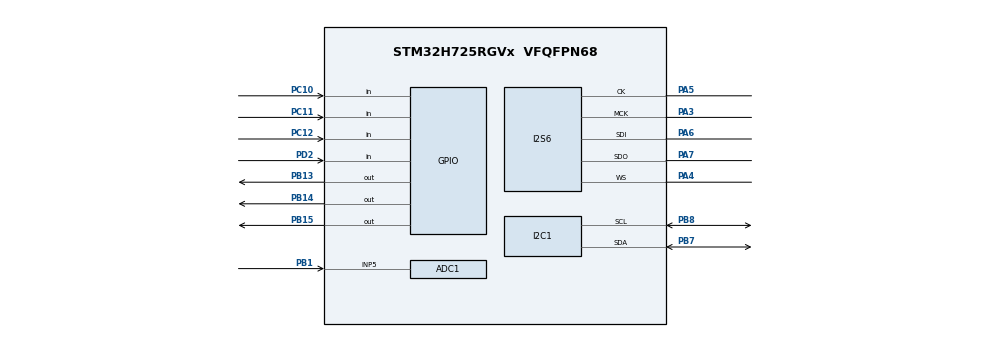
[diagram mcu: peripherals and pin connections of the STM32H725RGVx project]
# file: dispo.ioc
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ADC1.Channel-0\#ChannelRegularConversion=ADC_CHANNEL_5
ADC1.ContinuousConvMode=DISABLE
ADC1.EOCSelection=ADC_EOC_SINGLE_CONV
ADC1.NbrOfConversionFlag=1
ADC1.OffsetNumber-0\#ChannelRegularConversion=ADC_OFFSET_NONE
ADC1.OffsetSignedSaturation-0\#ChannelRegularConversion=DISABLE
ADC1.Overrun=ADC_OVR_DATA_PRESERVED
ADC1.Rank-0\#ChannelRegularConversion=1
ADC1.SamplingTime-0\#ChannelRegularConversion=ADC_SAMPLETIME_1CYCLE_5
ADC1.master=1
Bdma.Request0=SPI6_RX
Bdma.Request1=SPI6_TX
Bdma.RequestsNb=2
Bdma.SPI6_RX.0.Direction=DMA_PERIPH_TO_MEMORY
Bdma.SPI6_RX.0.EventEnable=DISABLE
Bdma.SPI6_RX.0.Instance=BDMA_Channel0
Bdma.SPI6_RX.0.MemDataAlignment=DMA_MDATAALIGN_HALFWORD
Bdma.SPI6_RX.0.MemInc=DMA_MINC_ENABLE
Bdma.SPI6_RX.0.Mode=DMA_CIRCULAR
Bdma.SPI6_RX.0.PeriphDataAlignment=DMA_PDATAALIGN_HALFWORD
Bdma.SPI6_RX.0.PeriphInc=DMA_PINC_DISABLE
Bdma.SPI6_RX.0.Polarity=HAL_DMAMUX_REQ_GEN_RISING
Bdma.SPI6_RX.0.Priority=DMA_PRIORITY_HIGH
Bdma.SPI6_RX.0.RequestNumber=1
Bdma.SPI6_RX.0.SignalID=NONE
Bdma.SPI6_RX.0.SyncEnable=DISABLE
Bdma.SPI6_RX.0.SyncPolarity=HAL_DMAMUX_SYNC_NO_EVENT
Bdma.SPI6_RX.0.SyncRequestNumber=1
Bdma.SPI6_RX.0.SyncSignalID=NONE
Bdma.SPI6_TX.1.Direction=DMA_MEMORY_TO_PERIPH
Bdma.SPI6_TX.1.EventEnable=DISABLE
Bdma.SPI6_TX.1.Instance=BDMA_Channel1
Bdma.SPI6_TX.1.MemDataAlignment=DMA_MDATAALIGN_HALFWORD
Bdma.SPI6_TX.1.MemInc=DMA_MINC_ENABLE
Bdma.SPI6_TX.1.Mode=DMA_CIRCULAR
Bdma.SPI6_TX.1.PeriphDataAlignment=DMA_PDATAALIGN_HALFWORD
Bdma.SPI6_TX.1.PeriphInc=DMA_PINC_DISABLE
Bdma.SPI6_TX.1.Polarity=HAL_DMAMUX_REQ_GEN_RISING
Bdma.SPI6_TX.1.Priority=DMA_PRIORITY_HIGH
Bdma.SPI6_TX.1.RequestNumber=1
Bdma.SPI6_TX.1.SignalID=NONE
Bdma.SPI6_TX.1.SyncEnable=DISABLE
Bdma.SPI6_TX.1.SyncPolarity=HAL_DMAMUX_SYNC_NO_EVENT
Bdma.SPI6_TX.1.SyncRequestNumber=1
Bdma.SPI6_TX.1.SyncSignalID=NONE
FREERTOS.Tasks01=defaultTask,24,128,StartDefaultTask,Default,NULL,Dynamic,NULL,NULL
FREERTOS.configUSE_NEWLIB_REENTRANT=1
I2C1.Timing=0x10C0ECFF
I2S6.AudioFreq=I2S_AUDIOFREQ_48K
I2S6.ErrorAudioFreq=-2.34 %
I2S6.Instance=SPI$Index
I2S6.RealAudioFreq=46.875 KHz
Mcu.Family=STM32H7
Mcu.Name=STM32H725RGVx
Mcu.Package=VFQFPN68
NVIC.BDMA_Channel0_IRQn=true\:5\:0\:false\:false\:true\:true\:false\:true\:true
NVIC.BDMA_Channel1_IRQn=true\:5\:0\:false\:false\:true\:true\:false\:true\:true
NVIC.PriorityGroup=NVIC_PRIORITYGROUP_4
NVIC.TIM1_UP_IRQn=true\:15\:0\:false\:false\:true\:false\:false\:true\:true
NVIC.TimeBase=TIM1_UP_IRQn
NVIC.TimeBaseIP=TIM1
PA13(JTMS/SWDIO).Mode=Trace_Asynchronous_SW
PA13(JTMS/SWDIO).Signal=DEBUG_JTMS-SWDIO
PA14(JTCK/SWCLK).Mode=Trace_Asynchronous_SW
PA14(JTCK/SWCLK).Signal=DEBUG_JTCK-SWCLK
PA3.Mode=Master_Clock_Activated
PA3.Signal=I2S6_MCK
PA4.Mode=Full_Duplex_Master
PA4.Signal=I2S6_WS
PA5.Mode=Full_Duplex_Master
PA5.Signal=I2S6_CK
PA6.Mode=Full_Duplex_Master
PA6.Signal=I2S6_SDI
PA7.Mode=Full_Duplex_Master
PA7.Signal=I2S6_SDO
PB1.Signal=ADCx_INP5
PB13.Signal=GPIO_Output
PB14.Signal=GPIO_Output
PB15.Signal=GPIO_Output
PB3(JTDO/TRACESWO).Mode=Trace_Asynchronous_SW
PB3(JTDO/TRACESWO).Signal=DEBUG_JTDO-SWO
PB7.Mode=I2C
PB7.Signal=I2C1_SDA
PB8.Mode=I2C
PB8.Signal=I2C1_SCL
PC10.Signal=GPIO_Input
PC11.Signal=GPIO_Input
PC12.Signal=GPIO_Input
PD2.Signal=GPIO_Input
PH0-OSC_IN.Mode=HSE-External-Oscillator
PH0-OSC_IN.Signal=RCC_OSC_IN
PH1-OSC_OUT.Mode=HSE-External-Oscillator
PH1-OSC_OUT.Signal=RCC_OSC_OUT
ProjectManager.HeapSize=0x200
ProjectManager.StackSize=0x400
ProjectManager.TargetToolchain=CMake
RCC.ADCCLockSelection=RCC_ADCCLKSOURCE_PLL3
RCC.ADCFreq_Value=2000000
RCC.APB1Freq_Value=100000000
RCC.APB2Freq_Value=100000000
RCC.APB3Freq_Value=100000000
RCC.APB4Freq_Value=100000000
RCC.CKPERSourceSelection=RCC_CLKPSOURCE_HSE
RCC.CortexFreq_Value=400000000
RCC.D1PPRE=RCC_APB3_DIV2
RCC.D2PPRE1=RCC_APB1_DIV2
RCC.D2PPRE2=RCC_APB2_DIV2
RCC.D3PPRE=RCC_APB4_DIV2
RCC.DIVM1=16
RCC.DIVM2=8
RCC.DIVN1=200
RCC.DIVN2=96
RCC.DIVN3=150
RCC.DIVP1=1
RCC.DIVP2=4
RCC.DIVQ2=4
RCC.DIVR3=75
RCC.HCLKFreq_Value=200000000
RCC.HPRE=RCC_HCLK_DIV2
RCC.HSE_VALUE=32000000
RCC.PLL2FRACN=0
RCC.PLL2_VCI_Range=RCC_PLL2VCIRANGE_3
RCC.PLL3FRACN=0
RCC.PLLFRACN=0
RCC.PLLSourceVirtual=RCC_PLLSOURCE_HSE
RCC.SPI6CLockSelection=RCC_SPI6CLKSOURCE_PLL2
RCC.SYSCLKFreq_VALUE=400000000
RCC.SYSCLKSource=RCC_SYSCLKSOURCE_PLLCLK
RCC.USBCLockSelection=RCC_USBCLKSOURCE_PLL3
RCC.USBFreq_Value=75000000
SH.ADCx_INP5.0=ADC1_INP5,IN5-Single-Ended
VP_FREERTOS_VS_CMSIS_V2.Mode=CMSIS_V2
VP_SYS_VS_tim1.Mode=TIM1
board=custom

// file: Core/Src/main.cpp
/* USER CODE BEGIN Header */
/**
  ******************************************************************************
  * @file           : main.c
  * @brief          : Main program body
  ******************************************************************************
  * @attention
  *
  * Copyright (c) 2026 STMicroelectronics.
  * All rights reserved.
  *
  * This software is licensed under terms that can be found in the LICENSE file
  * in the root directory of this software component.
  * If no LICENSE file comes with this software, it is provided AS-IS.
  *
  ******************************************************************************
  */
/* USER CODE END Header */
#include "main.h"
#include "FreeRTOS.h"
#include "cmsis_os2.h"
#include "adc.h"
#include "bdma.h"
#include "i2c.h"
#include "i2s.h"
#include "gpio.h"

/* USER CODE BEGIN Includes */
#include "audio_proc.hpp"
/* USER CODE END Includes */

void SystemClock_Config(void);
extern void MX_FREERTOS_Init(void);

int main(void)
{

  /* MCU Configuration--------------------------------------------------------*/

  /* Reset of all peripherals, Initializes the Flash interface and the Systick. */
  HAL_Init();

  /* Configure the system clock */
  SystemClock_Config();

  /* Initialize all configured peripherals */
  MX_GPIO_Init();
  MX_BDMA_Init();
  MX_I2C1_Init();
  MX_ADC1_Init();
  MX_I2S6_Init();

  /* Init scheduler */
  osKernelInitialize();  /* Call init function for freertos objects (in cmsis_os2.c) */
  MX_FREERTOS_Init();

  /* Start scheduler */
  osKernelStart();

  /* We should never get here as control is now taken by the scheduler */

  /* Infinite loop */
  while (1)
  {

  }
}

void SystemClock_Config(void)
{
  RCC_OscInitTypeDef RCC_OscInitStruct = {0};
  RCC_ClkInitTypeDef RCC_ClkInitStruct = {0};

  /** Supply configuration update enable
  */
  HAL_PWREx_ConfigSupply(PWR_DIRECT_SMPS_SUPPLY);

  /** Configure the main internal regulator output voltage
  */
  __HAL_PWR_VOLTAGESCALING_CONFIG(PWR_REGULATOR_VOLTAGE_SCALE1);

  while(!__HAL_PWR_GET_FLAG(PWR_FLAG_VOSRDY)) {}

  /** Initializes the RCC Oscillators according to the specified parameters
  * in the RCC_OscInitTypeDef structure.
  */
  RCC_OscInitStruct.OscillatorType = RCC_OSCILLATORTYPE_HSE;
  RCC_OscInitStruct.HSEState = RCC_HSE_ON;
  RCC_OscInitStruct.PLL.PLLState = RCC_PLL_ON;
  RCC_OscInitStruct.PLL.PLLSource = RCC_PLLSOURCE_HSE;
  RCC_OscInitStruct.PLL.PLLM = 16;
  RCC_OscInitStruct.PLL.PLLN = 200;
  RCC_OscInitStruct.PLL.PLLP = 1;
  RCC_OscInitStruct.PLL.PLLQ = 2;
  RCC_OscInitStruct.PLL.PLLR = 2;
  RCC_OscInitStruct.PLL.PLLRGE = RCC_PLL1VCIRANGE_1;
  RCC_OscInitStruct.PLL.PLLVCOSEL = RCC_PLL1VCOWIDE;
  RCC_OscInitStruct.PLL.PLLFRACN = 0;
  if (HAL_RCC_OscConfig(&RCC_OscInitStruct) != HAL_OK)
  {
    Error_Handler();
  }

  /** Initializes the CPU, AHB and APB buses clocks
  */
  RCC_ClkInitStruct.ClockType = RCC_CLOCKTYPE_HCLK|RCC_CLOCKTYPE_SYSCLK
                              |RCC_CLOCKTYPE_PCLK1|RCC_CLOCKTYPE_PCLK2
                              |RCC_CLOCKTYPE_D3PCLK1|RCC_CLOCKTYPE_D1PCLK1;
  RCC_ClkInitStruct.SYSCLKSource = RCC_SYSCLKSOURCE_PLLCLK;
  RCC_ClkInitStruct.SYSCLKDivider = RCC_SYSCLK_DIV1;
  RCC_ClkInitStruct.AHBCLKDivider = RCC_HCLK_DIV2;
  RCC_ClkInitStruct.APB3CLKDivider = RCC_APB3_DIV2;
  RCC_ClkInitStruct.APB1CLKDivider = RCC_APB1_DIV2;
  RCC_ClkInitStruct.APB2CLKDivider = RCC_APB2_DIV2;
  RCC_ClkInitStruct.APB4CLKDivider = RCC_APB4_DIV2;

  if (HAL_RCC_ClockConfig(&RCC_ClkInitStruct, FLASH_LATENCY_2) != HAL_OK)
  {
    Error_Handler();
  }
}

void HAL_TIM_PeriodElapsedCallback(TIM_HandleTypeDef *htim)
{
  if (htim->Instance == TIM1)
  {
    HAL_IncTick();
  }
}

void Error_Handler(void)
{
  __disable_irq();
  while (1)
  {
  }
}
